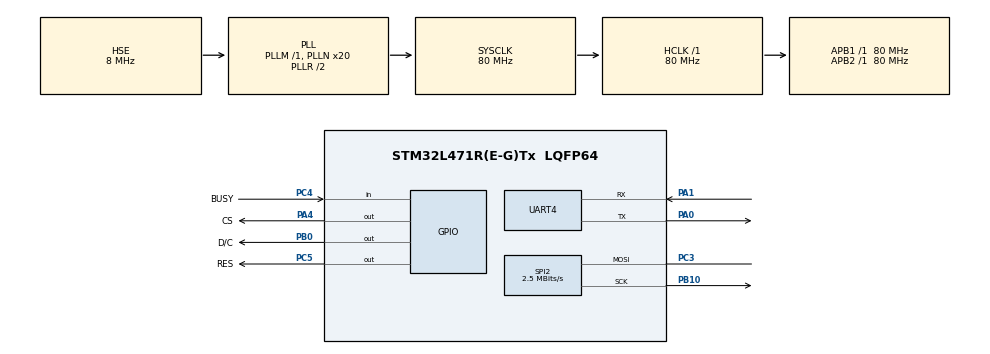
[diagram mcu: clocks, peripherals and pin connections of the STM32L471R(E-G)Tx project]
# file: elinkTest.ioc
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Dma.Request0=SPI2_TX
Dma.Request1=UART4_TX
Dma.SPI2_TX.0.Direction=DMA_MEMORY_TO_PERIPH
Dma.SPI2_TX.0.Instance=DMA1_Channel5
Dma.SPI2_TX.0.MemDataAlignment=DMA_MDATAALIGN_BYTE
Dma.SPI2_TX.0.MemInc=DMA_MINC_ENABLE
Dma.SPI2_TX.0.Mode=DMA_NORMAL
Dma.SPI2_TX.0.PeriphDataAlignment=DMA_PDATAALIGN_BYTE
Dma.SPI2_TX.0.PeriphInc=DMA_PINC_DISABLE
Dma.SPI2_TX.0.Priority=DMA_PRIORITY_LOW
Dma.UART4_TX.1.Direction=DMA_MEMORY_TO_PERIPH
Dma.UART4_TX.1.Instance=DMA2_Channel3
Dma.UART4_TX.1.MemDataAlignment=DMA_MDATAALIGN_BYTE
Dma.UART4_TX.1.MemInc=DMA_MINC_ENABLE
Dma.UART4_TX.1.Mode=DMA_NORMAL
Dma.UART4_TX.1.PeriphDataAlignment=DMA_PDATAALIGN_BYTE
Dma.UART4_TX.1.PeriphInc=DMA_PINC_DISABLE
Dma.UART4_TX.1.Priority=DMA_PRIORITY_LOW
Mcu.Family=STM32L4
Mcu.Name=STM32L471R(E-G)Tx
Mcu.Package=LQFP64
NVIC.DMA1_Channel5_IRQn=true\:0\:0\:false\:false\:true\:false\:true\:true
NVIC.DMA2_Channel3_IRQn=true\:0\:0\:false\:false\:true\:false\:true\:true
NVIC.PriorityGroup=NVIC_PRIORITYGROUP_4
NVIC.SPI2_IRQn=true\:0\:0\:false\:false\:true\:true\:true\:true
PA0.Mode=Asynchronous
PA0.Signal=UART4_TX
PA1.Mode=Asynchronous
PA1.Signal=UART4_RX
PA13\ (JTMS-SWDIO).Mode=Serial_Wire
PA13\ (JTMS-SWDIO).Signal=SYS_JTMS-SWDIO
PA14\ (JTCK-SWCLK).Mode=Serial_Wire
PA14\ (JTCK-SWCLK).Signal=SYS_JTCK-SWCLK
PA4.GPIO_Label=CS
PA4.PinState=GPIO_PIN_SET
PA4.Signal=GPIO_Output
PB0.GPIO_Label=D/C
PB0.Signal=GPIO_Output
PB10.Mode=Simplex_Bidirectional_Master
PB10.Signal=SPI2_SCK
PC14-OSC32_IN\ (PC14).Mode=LSE-External-Oscillator
PC14-OSC32_IN\ (PC14).Signal=RCC_OSC32_IN
PC15-OSC32_OUT\ (PC15).Mode=LSE-External-Oscillator
PC15-OSC32_OUT\ (PC15).Signal=RCC_OSC32_OUT
PC3.Mode=Simplex_Bidirectional_Master
PC3.Signal=SPI2_MOSI
PC4.GPIO_Label=BUSY
PC4.GPIO_PuPd=GPIO_PULLUP
PC4.Signal=GPIO_Input
PC5.GPIO_Label=RES
PC5.PinState=GPIO_PIN_SET
PC5.Signal=GPIO_Output
PH0-OSC_IN\ (PH0).Mode=HSE-External-Oscillator
PH0-OSC_IN\ (PH0).Signal=RCC_OSC_IN
PH1-OSC_OUT\ (PH1).Mode=HSE-External-Oscillator
PH1-OSC_OUT\ (PH1).Signal=RCC_OSC_OUT
ProjectManager.HeapSize=0x200
ProjectManager.StackSize=0x400
ProjectManager.TargetToolchain=MDK-ARM V5.32
RCC.ADCFreq_Value=32000000
RCC.AHBFreq_Value=80000000
RCC.APB1Freq_Value=80000000
RCC.APB1TimFreq_Value=80000000
RCC.APB2Freq_Value=80000000
RCC.APB2TimFreq_Value=80000000
RCC.CortexFreq_Value=80000000
RCC.HCLKFreq_Value=80000000
RCC.HSE_VALUE=8000000
RCC.HSI_VALUE=16000000
RCC.MSI_VALUE=4000000
RCC.PLLN=20
RCC.PLLSourceVirtual=RCC_PLLSOURCE_HSE
RCC.RTCClockSelection=RCC_RTCCLKSOURCE_LSE
RCC.SYSCLKFreq_VALUE=80000000
RCC.SYSCLKSource=RCC_SYSCLKSOURCE_PLLCLK
RCC.VCOOutputFreq_Value=160000000
SPI2.BaudRatePrescaler=SPI_BAUDRATEPRESCALER_32
SPI2.CalculateBaudRate=2.5 MBits/s
SPI2.DataSize=SPI_DATASIZE_8BIT
SPI2.Direction=SPI_DIRECTION_1LINE
SPI2.Mode=SPI_MODE_MASTER
SPI2.NSSPMode=SPI_NSS_PULSE_DISABLE
SPI2.VirtualType=VM_MASTER
VP_RTC_VS_RTC_Activate.Mode=RTC_Enabled
VP_RTC_VS_RTC_Calendar.Mode=RTC_Calendar
board=custom

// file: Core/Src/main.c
/* USER CODE BEGIN Header */
/**
  ******************************************************************************
  * @file           : main.c
  * @brief          : Main program body
  ******************************************************************************
  * @attention
  *
  * Copyright (c) 2026 STMicroelectronics.
  * All rights reserved.
  *
  * This software is licensed under terms that can be found in the LICENSE file
  * in the root directory of this software component.
  * If no LICENSE file comes with this software, it is provided AS-IS.
  *
  ******************************************************************************
  */
/* USER CODE END Header */
#include "main.h"
#include "dma.h"
#include "rtc.h"
#include "spi.h"
#include "usart.h"
#include "gpio.h"

/* USER CODE BEGIN Includes */
#include "../../app/epd_bringup.h"
/* USER CODE END Includes */

void SystemClock_Config(void);

int main(void)
{

  /* MCU Configuration--------------------------------------------------------*/

  /* Reset of all peripherals, Initializes the Flash interface and the Systick. */
  HAL_Init();

  /* Configure the system clock */
  SystemClock_Config();

  /* Initialize all configured peripherals */
  MX_GPIO_Init();
  MX_DMA_Init();
  MX_RTC_Init();
  MX_SPI2_Init();
  MX_UART4_Init();
  /* USER CODE BEGIN 2 */
  (void)epd_bringup_run_clock();
  /* USER CODE END 2 */

  /* Infinite loop */
  while (1)
  {

  }
}

void SystemClock_Config(void)
{
  RCC_OscInitTypeDef RCC_OscInitStruct = {0};
  RCC_ClkInitTypeDef RCC_ClkInitStruct = {0};

  /** Configure the main internal regulator output voltage
  */
  if (HAL_PWREx_ControlVoltageScaling(PWR_REGULATOR_VOLTAGE_SCALE1) != HAL_OK)
  {
    Error_Handler();
  }

  /** Configure LSE Drive Capability
  */
  HAL_PWR_EnableBkUpAccess();
  __HAL_RCC_LSEDRIVE_CONFIG(RCC_LSEDRIVE_LOW);

  /** Initializes the RCC Oscillators according to the specified parameters
  * in the RCC_OscInitTypeDef structure.
  */
  RCC_OscInitStruct.OscillatorType = RCC_OSCILLATORTYPE_HSE|RCC_OSCILLATORTYPE_LSE;
  RCC_OscInitStruct.HSEState = RCC_HSE_ON;
  RCC_OscInitStruct.LSEState = RCC_LSE_ON;
  RCC_OscInitStruct.PLL.PLLState = RCC_PLL_ON;
  RCC_OscInitStruct.PLL.PLLSource = RCC_PLLSOURCE_HSE;
  RCC_OscInitStruct.PLL.PLLM = 1;
  RCC_OscInitStruct.PLL.PLLN = 20;
  RCC_OscInitStruct.PLL.PLLP = RCC_PLLP_DIV7;
  RCC_OscInitStruct.PLL.PLLQ = RCC_PLLQ_DIV2;
  RCC_OscInitStruct.PLL.PLLR = RCC_PLLR_DIV2;
  if (HAL_RCC_OscConfig(&RCC_OscInitStruct) != HAL_OK)
  {
    Error_Handler();
  }

  /** Initializes the CPU, AHB and APB buses clocks
  */
  RCC_ClkInitStruct.ClockType = RCC_CLOCKTYPE_HCLK|RCC_CLOCKTYPE_SYSCLK
                              |RCC_CLOCKTYPE_PCLK1|RCC_CLOCKTYPE_PCLK2;
  RCC_ClkInitStruct.SYSCLKSource = RCC_SYSCLKSOURCE_PLLCLK;
  RCC_ClkInitStruct.AHBCLKDivider = RCC_SYSCLK_DIV1;
  RCC_ClkInitStruct.APB1CLKDivider = RCC_HCLK_DIV1;
  RCC_ClkInitStruct.APB2CLKDivider = RCC_HCLK_DIV1;

  if (HAL_RCC_ClockConfig(&RCC_ClkInitStruct, FLASH_LATENCY_4) != HAL_OK)
  {
    Error_Handler();
  }
}

void Error_Handler(void)
{
  __disable_irq();
  while (1)
  {
  }
}
